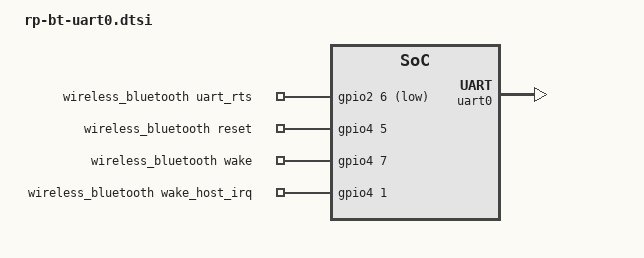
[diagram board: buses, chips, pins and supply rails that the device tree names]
/{
    wireless_bluetooth: wireless-bluetooth {
        compatible = "bluetooth-platdata";
        uart_rts_gpios = <&gpio2 6 GPIO_ACTIVE_LOW>;
        pinctrl-names = "default","rts_gpio";
        pinctrl-0 = <&uart0m1_rtsn>;
        pinctrl-1 = <&uart0_rts_gpio>;

        //keep_bt_power_on;
        /* BT,power_gpio = <&gpio* *** GPIO_ACTIVE_HIGH>; */
        BT,reset_gpio = <&gpio4 5 GPIO_ACTIVE_HIGH>;
        BT,wake_gpio = <&gpio4 7 GPIO_ACTIVE_HIGH>;
        BT,wake_host_irq = <&gpio4 1 GPIO_ACTIVE_HIGH>;

        status = "okay";
    };
};

&pinctrl {
    wireless-bluetooth {
        uart0_rts_gpio: uart0-rts-gpio {
            rockchip,pins = <2 RK_PA6 RK_FUNC_GPIO &pcfg_pull_none>;
        };
    };
};

&uart0 {
    pinctrl-names = "default";
    pinctrl-0 = <&uart0m1_xfer &uart0m1_ctsn>;
    status = "okay";
};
